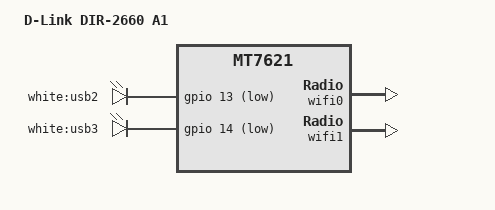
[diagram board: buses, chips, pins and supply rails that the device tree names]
// SPDX-License-Identifier: GPL-2.0-or-later OR MIT

#include "mt7621_dlink_dir-xx60-a1.dtsi"

/ {
	compatible = "dlink,dir-2660-a1", "mediatek,mt7621-soc";
	model = "D-Link DIR-2660 A1";
};

&leds {
	usb2_white {
		label = "white:usb2";
		gpios = <&gpio 13 GPIO_ACTIVE_LOW>;
		trigger-sources = <&ehci_port2>;
		linux,default-trigger = "usbport";
	};

	usb3_white {
		label = "white:usb3";
		gpios = <&gpio 14 GPIO_ACTIVE_LOW>;
		trigger-sources = <&xhci_ehci_port1>;
		linux,default-trigger = "usbport";
	};
};

&wifi0 {
	nvmem-cells = <&macaddr_factory_e000>;
	nvmem-cell-names = "mac-address";
	mac-address-increment = <1>;
};

&wifi1 {
	nvmem-cells = <&macaddr_factory_e000>;
	nvmem-cell-names = "mac-address";
	mac-address-increment = <2>;
};
